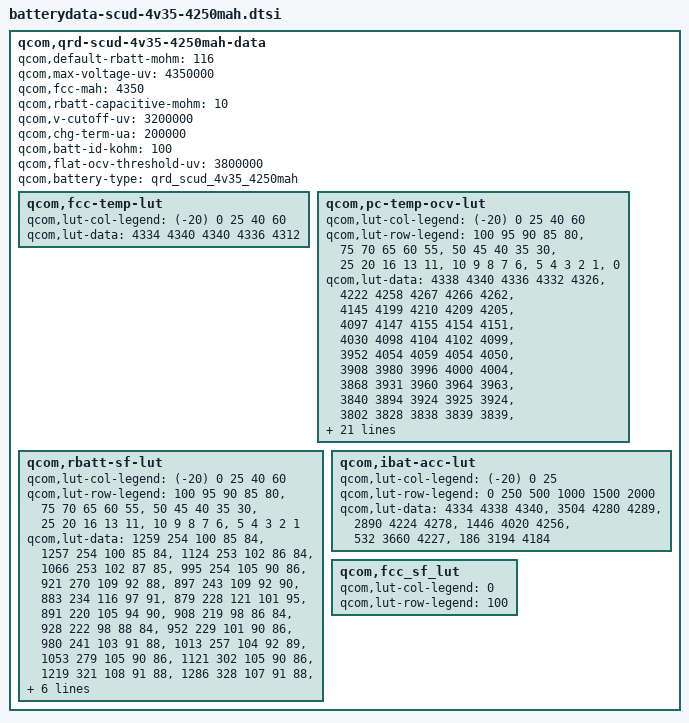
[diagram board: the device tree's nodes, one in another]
/* Copyright (c) 2014, The Linux Foundation. All rights reserved.
 *
 * This program is free software; you can redistribute it and/or modify
 * it under the terms of the GNU General Public License version 2 and
 * only version 2 as published by the Free Software Foundation.
 *
 * This program is distributed in the hope that it will be useful,
 * but WITHOUT ANY WARRANTY; without even the implied warranty of
 * MERCHANTABILITY or FITNESS FOR A PARTICULAR PURPOSE.  See the
 * GNU General Public License for more details.
 */

qcom,qrd-scud-4v35-4250mah-data {
	qcom,default-rbatt-mohm = <116>;
	qcom,max-voltage-uv = <4350000>;
	qcom,fcc-mah = <4350>;
	qcom,rbatt-capacitive-mohm = <10>;
	qcom,v-cutoff-uv = <3200000>;
	qcom,chg-term-ua = <200000>;
	qcom,batt-id-kohm = <100>;
	qcom,flat-ocv-threshold-uv = <3800000>;
	qcom,battery-type = "qrd_scud_4v35_4250mah";

	qcom,fcc-temp-lut {
		qcom,lut-col-legend = <(-20) 0 25 40 60>;
		qcom,lut-data = <4334 4340 4340 4336 4312>;
	};

	qcom,pc-temp-ocv-lut {
		qcom,lut-col-legend = <(-20) 0 25 40 60>;
		qcom,lut-row-legend = <100 95 90 85 80>,
				<75 70 65 60 55>,
				<50 45 40 35 30>,
				<25 20 16 13 11>,
				<10 9 8 7 6 >,
				<5 4 3 2 1 >,
				<0>;
		qcom,lut-data = <4338 4340 4336 4332 4326>,
				<4222 4258 4267 4266 4262>,
				<4145 4199 4210 4209 4205>,
				<4097 4147 4155 4154 4151>,
				<4030 4098 4104 4102 4099>,
				<3952 4054 4059 4054 4050>,
				<3908 3980 3996 4000 4004>,
				<3868 3931 3960 3964 3963>,
				<3840 3894 3924 3925 3924>,
				<3802 3828 3838 3839 3839>,
				<3769 3791 3797 3797 3796>,
				<3752 3780 3783 3782 3780>,
				<3735 3770 3772 3770 3764>,
				<3717 3760 3760 3752 3740>,
				<3698 3742 3742 3733 3720>,
				<3683 3718 3721 3714 3700>,
				<3670 3694 3700 3692 3681>,
				<3658 3678 3686 3680 3670>,
				<3651 3672 3684 3678 3668>,
				<3644 3666 3681 3676 3667>,
				<3635 3659 3677 3674 3666>,
				<3624 3650 3672 3670 3662>,
				<3611 3642 3662 3661 3655>,
				<3602 3635 3653 3657 3645>,
				<3593 3628 3644 3642 3636>,
				<3566 3602 3610 3602 3597>,
				<3526 3554 3556 3545 3540>,
				<3470 3484 3486 3470 3466>,
				<3381 3388 3392 3370 3368>,
				<3290 3298 3296 3288 3284>,
				<3200 3208 3200 3206 3200>;
	};

	qcom,rbatt-sf-lut {
		qcom,lut-col-legend = <(-20) 0 25 40 60>;
		qcom,lut-row-legend = <100 95 90 85 80>,
				<75 70 65 60 55>,
				<50 45 40 35 30>,
				<25 20 16 13 11>,
				<10 9 8 7 6>,
				<5 4 3 2 1>;
		qcom,lut-data = <1259 254 100 85 84>,
				<1257 254 100 85 84>,
				<1124 253 102 86 84>,
				<1066 253 102 87 85>,
				<995 254 105 90 86>,
				<921 270 109 92 88>,
				<897 243 109 92 90>,
				<883 234 116 97 91>,
				<879 228 121 101 95>,
				<891 220 105 94 90>,
				<908 219 98 86 84>,
				<928 222 98 88 84>,
				<952 229 101 90 86>,
				<980 241 103 91 88>,
				<1013 257 104 92 89>,
				<1053 279 105 90 86>,
				<1121 302 105 90 86>,
				<1219 321 108 91 88>,
				<1286 328 107 91 88>,
				<1309 333 107 89 86>,
				<1384 341 109 91 87>,
				<1495 353 112 94 90>,
				<1616 365 117 97 91>,
				<1766 378 123 99 93>,
				<1948 397 129 103 95>,
				<2176 415 133 102 93>,
				<2471 430 128 99 90>,
				<2884 449 128 99 90>,
				<3500 482 129 100 92>,
				<4446 541 134 104 97>;
	};

	qcom,ibat-acc-lut {
		qcom,lut-col-legend = <(-20) 0 25>;
		qcom,lut-row-legend = <0 250 500 1000 1500 2000>;
		qcom,lut-data = <4334 4338 4340>,
			        <3504 4280 4289>,
			        <2890 4224 4278>,
			        <1446 4020 4256>,
			        <532 3660 4227>,
			        <186 3194 4184>;
	};
	qcom,fcc_sf_lut {
		qcom,lut-col-legend = <0>;
		qcom,lut-row-legend = <100>;
	};
};
